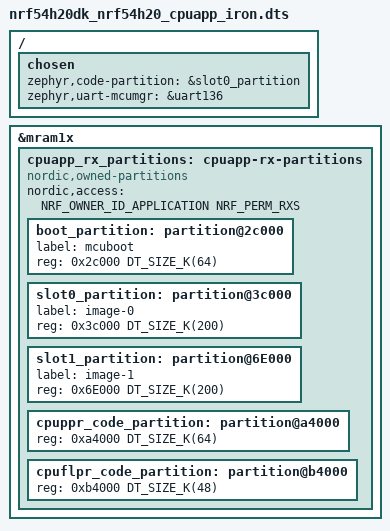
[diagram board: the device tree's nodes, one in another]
/*
 * Copyright (c) 2025 Nordic Semiconductor ASA
 *
 * SPDX-License-Identifier: Apache-2.0
 */

#include "nrf54h20dk_nrf54h20_cpuapp.dts"

/delete-node/&cpurad_rx_partitions;
/delete-node/&cpuapp_rx_partitions;

/* This is not yet an exhaustive memory map, and contain only a minimum required to boot
 * the application core.
 */

/ {
	chosen {
		zephyr,code-partition = &slot0_partition;
		zephyr,uart-mcumgr = &uart136;
	};
};

&mram1x {
	cpuapp_rx_partitions: cpuapp-rx-partitions {
		compatible = "nordic,owned-partitions", "fixed-partitions";
		nordic,access = <NRF_OWNER_ID_APPLICATION NRF_PERM_RXS>;
		#address-cells = <1>;
		#size-cells = <1>;

		boot_partition: partition@2c000 {
			label = "mcuboot";
			reg = <0x2c000 DT_SIZE_K(64)>;
		};

		slot0_partition: partition@3c000 {
			label = "image-0";
			reg = <0x3c000 DT_SIZE_K(200)>;
		};

		slot1_partition: partition@6E000 {
			label = "image-1";
			reg = <0x6E000 DT_SIZE_K(200)>;
		};

		cpuppr_code_partition: partition@a4000 {
			reg = <0xa4000 DT_SIZE_K(64)>;
		};

		cpuflpr_code_partition: partition@b4000 {
			reg = <0xb4000 DT_SIZE_K(48)>;
		};
	};
};
